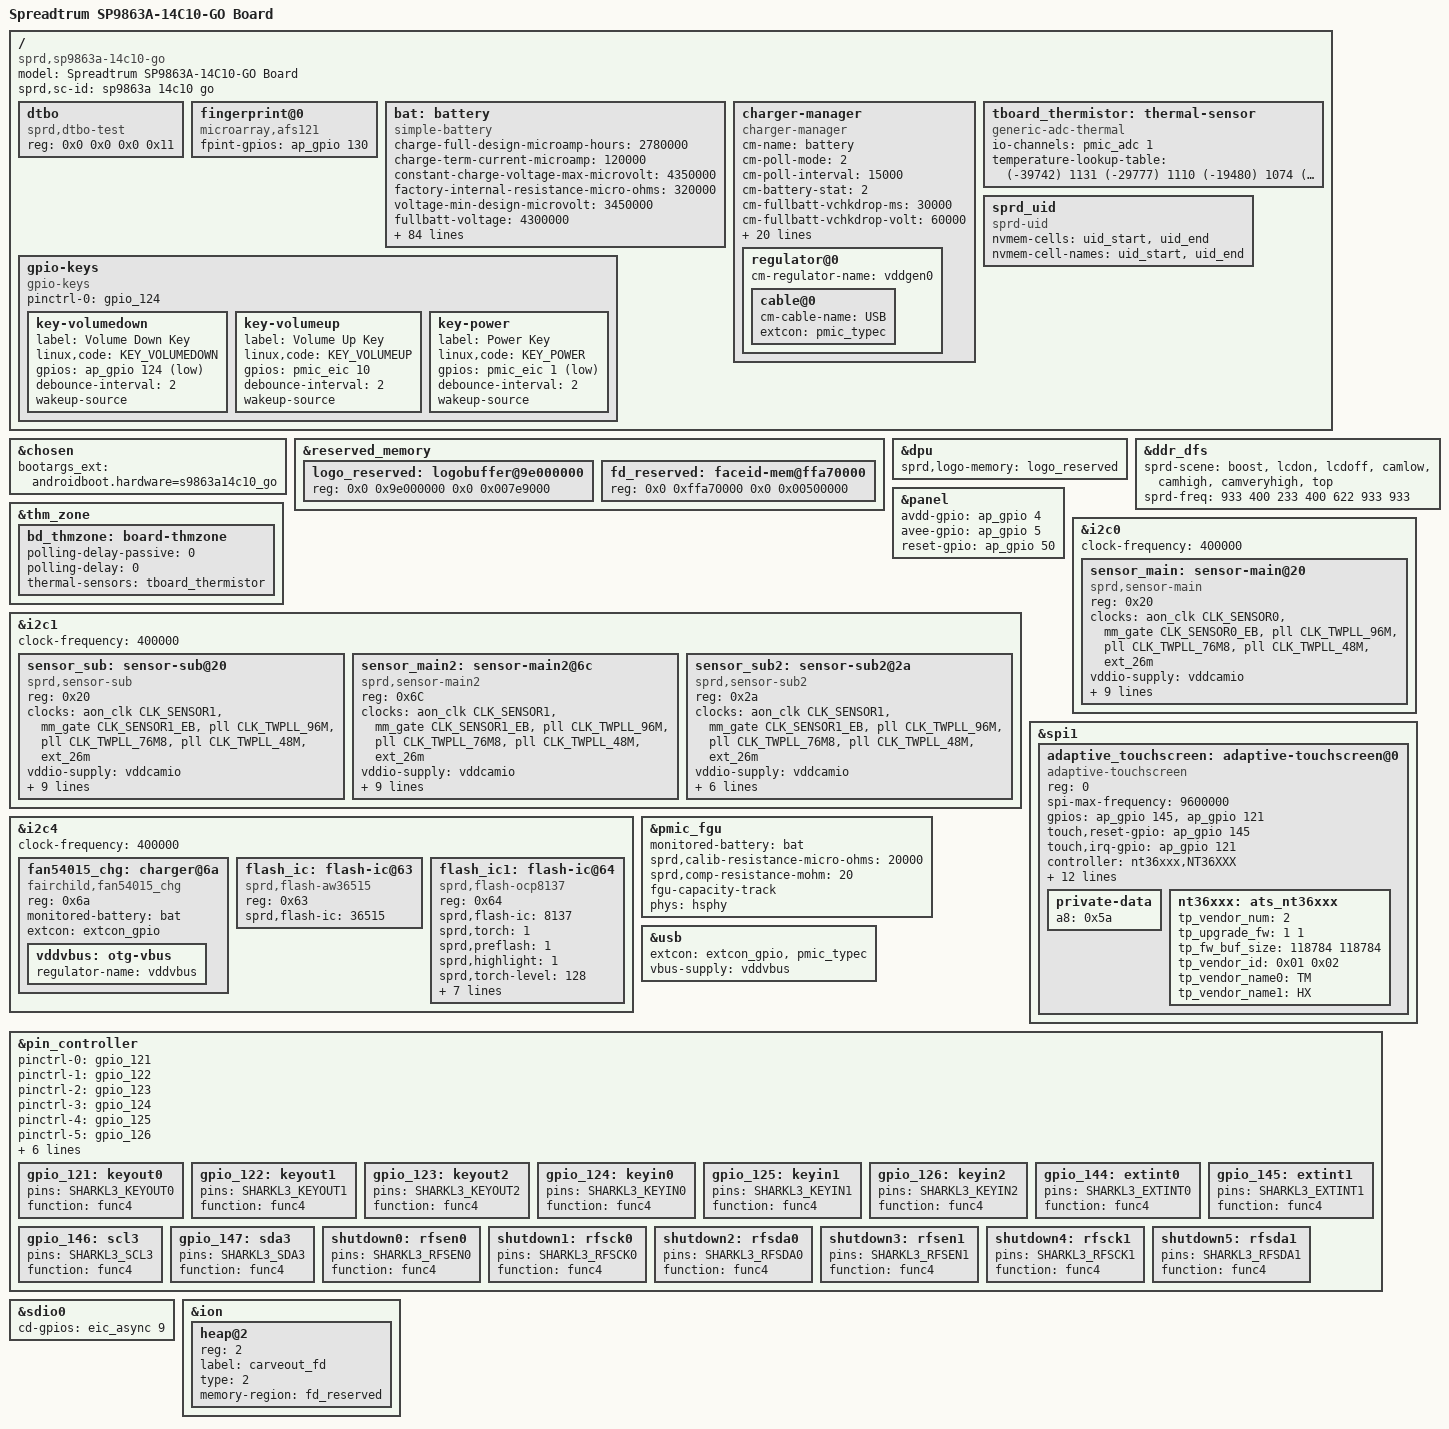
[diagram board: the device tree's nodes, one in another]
/dts-v1/;
/plugin/;
#include <dt-bindings/input/input.h>
#include <dt-bindings/gpio/gpio.h>
#include <dt-bindings/clock/sprd,sc9863a-clk.h>
#include "lcd/lcd_nt36525b_tm_mipi_hdp.dtsi"
#include "lcd/lcd_nt36525b_hx_mipi_hdp.dtsi"
#include "lcd/lcd_dummy_mipi.dtsi"

/ {
	model = "Spreadtrum SP9863A-14C10-GO Board";

	compatible = "sprd,sp9863a-14c10-go", "sprd,sc9863a";

	sprd,sc-id = "sp9863a 14c10 go";

	fragment {
		target-path = "/";
		__overlay__ {
			#address-cells = <2>;
			#size-cells = <2>;
			dtbo: dtbo {
				compatible = "sprd,dtbo-test";
				reg = <0x0 0x0 0x0 0x11>;
			};

			fingerprint@0 {
				compatible = "microarray,afs121";
				fpint-gpios = <&ap_gpio 130 0>;
			};

			bat: battery {
				compatible = "simple-battery";
				charge-full-design-microamp-hours = <2780000>;
				charge-term-current-microamp = <120000>;
				constant-charge-voltage-max-microvolt = <4350000>;
				factory-internal-resistance-micro-ohms = <320000>;
				voltage-min-design-microvolt = <3450000>;
				fullbatt-voltage = <4300000>;
				fullbatt-current = <120000>;
				fullbatt-track-end-vol = <4295000>;
				fullbatt-track-end-cur = <130000>;
				first-calib-voltage = <3554800>;
				first-calib-capacity = <50>;

				ocv-capacity-celsius = <20>;
				ocv-capacity-table-0 = <4330000 100>, <4249000 95>, <4189000 90>,
							<4133000 85>, <4081000 80>, <4034000 75>,
							<3991000 70>, <3953000 65>, <3910000 60>,
							<3866000 55>, <3836000 50>, <3813000 45>,
							<3795000 40>, <3782000 35>, <3774000 30>,
							<3765000 25>, <3750000 20>, <3726000 15>,
							<3687000 10>, <3658000 5>, <3400000 0>;
				voltage-temp-table = <1110270 800>, <999440 850>, <890430 900>,
							<785590 950>, <687630 1000>, <598220 1050>,
							<517680 1100>, <446100 1150>, <383390 1200>,
							<328950 1250>, <281840 1300>, <241480 1350>,
							<207030 1400>, <177580 1450>, <152490 1500>,
							<131160 1550>, <113000 1600>, <97790 1650>;
				capacity-temp-table = <25 100>, <10 97>, <(-10) 60>;
				resistance-temp-table = <20 100>, <10 243>, <(-10) 468>;

				battery-internal-resistance-celsius = <(-20)>, <(-10)>, <0>, <10>,
					<25>, <35>, <45>, <55>;
				battery-internal-resistance-table-0 = <1224>, <1224>, <1140>,
					<1084>, <1034>, <1001>, <994>, <992>, <992>, <992>,
					<996>, <1002>, <1010>, <1024>, <1045>, <1072>, <1180>,
					<1393>, <1756>, <2461>, <4272>;
				battery-internal-resistance-table-1 = <893>, <893>, <818>, <767>,
					<743>, <705>, <685>, <684>, <678>, <675>, <672>, <673>,
					<679>, <691>, <709>, <734>, <765>, <799>, <839>, <899>,
					<1092>;
				battery-internal-resistance-table-2 = <407>, <407>, <402>, <423>,
					<429>, <428>, <409>, <416>, <408>, <395>, <390>, <390>,
					<393>, <398>, <405>, <416>, <431>, <452>, <492>, <585>,
					<730>;
				battery-internal-resistance-table-3 = <381>, <381>, <378>, <371>,
					<366>, <374>, <358>, <364>, <349>, <332>, <327>, <329>,
					<334>, <340>, <350>, <366>, <386>, <417>, <475>, <585>,
					<771>;
				battery-internal-resistance-table-4 = <182>, <182>, <179>, <179>,
					<179>, <181>, <182>, <195>, <194>, <173>, <164>, <164>,
					<167>, <171>, <175>, <174>, <172>, <179>, <187>, <244>,
					<311>;
				battery-internal-resistance-table-5 = <168>, <168>, <175>, <172>,
					<171>, <171>, <173>, <184>, <176>, <153>, <147>, <147>,
					<150>, <153>, <156>, <152>, <149>, <154>, <158>, <206>,
					<255>;
				battery-internal-resistance-table-6 = <123>, <123>, <122>, <122>,
					<123>, <126>, <130>, <138>, <143>, <120>, <115>, <116>,
					<119>, <124>, <129>, <120>, <117>, <119>, <117>, <139>,
					<156>;
				battery-internal-resistance-table-7 = <106>, <106>, <106>, <106>,
					<108>, <110>, <113>, <119>, <128>, <107>, <104>, <105>,
					<108>, <112>, <117>, <107>, <106>, <107>, <105>, <127>,
					<140>;
				battery-internal-resistance-ocv-table = <4339000>, <4276000>,
					<4221000>, <4169000>, <4118000>, <4072000>, <4022000>,
					<3983000>, <3942000>, <3892000>, <3857000>, <3833000>,
					<3813000>, <3797000>, <3783000>, <3766000>, <3746000>,
					<3723000>, <3693000>, <3680000>, <3439000>;

				charge-sdp-current-microamp = <500000 500000>;
				charge-dcp-current-microamp = <1150000 3000000>;
				charge-cdp-current-microamp = <1150000 1150000>;
				charge-unknown-current-microamp = <500000 500000>;

				dcp-jeita-temp-table = <1000 1030 0 4350000>,
					<1150 1180 700000 4350000>,
					<1450 1420 1150000 4350000>,
					<1600 1570 700000 4100000>;
				sdp-jeita-temp-table = <1000 1030 0 4350000>,
					<1150 1180 500000 4350000>,
					<1450 1420 500000 4350000>,
					<1600 1570 500000 4100000>;
				cdp-jeita-temp-table = <1000 1030 0 4350000>,
					<1150 1180 700000 4350000>,
					<1450 1420 1150000 4350000>,
					<1600 1570 700000 4100000>;
				unknown-jeita-temp-table = <1000 1030 0 4350000>,
					<1150 1180 500000 4350000>,
					<1450 1420 500000 4350000>,
					<1600 1570 500000 4100000>;
				force-jeita-status = <2>;
			};

			charger-manager {
				status = "okay";
				compatible = "charger-manager";
				cm-name = "battery";
				cm-poll-mode = <2>;
				cm-poll-interval = <15000>;
				cm-battery-stat = <2>;

				cm-fullbatt-vchkdrop-ms = <30000>;
				cm-fullbatt-vchkdrop-volt = <60000>;
				cm-fullbatt-capacity = <100>;

				cm-chargers = "fan54015_charger";
				cm-fuel-gauge = "sc27xx-fgu";

				/* in deci centigrade */
				cm-battery-cold = <200>;
				cm-battery-cold-in-minus;
				cm-battery-hot = <800>;
				cm-battery-temp-diff = <100>;

				/* Allow charging for 6hr */
				cm-charging-max = <21600000>;
				/* recovery charging after stop charging 45min */
				cm-discharging-max = <2700000>;

				/* the interval to feed charger watchdog */
				cm-wdt-interval = <60>;

				/* drop voltage in microVolts to allow shutdown */
				cm-shutdown-voltage = <3100000>;

				/* when 99% of the time is exceeded, it will be forced to 100% */
				cm-tickle-time-out = <1500>;

				/* how much time to allow capacity change */
				cm-one-cap-time = <30>;

				/* when the safe charging voltage is exceeded, stop charging */
				cm-charge-voltage-max = <6500000>;
				/* drop voltage in microVolts to restart charging */
				cm-charge-voltage-drop = <700000>;

				monitored-battery = <&bat>;

				cm-thermal-zone = "board-thmzone";

				cm-cap-remap-table = <1 2 3>, <2 3 2>, <98 99 2>, <99 100 3>;

				phys = <&hsphy>;

				regulator@0 {
					cm-regulator-name = "vddgen0";
					cable@0 {
						cm-cable-name = "USB";
						extcon = <&pmic_typec>;
					};
				};
			};

			tboard_thermistor:thermal-sensor {
				compatible = "generic-adc-thermal";
				#thermal-sensor-cells = <0>;
				io-channels = <&pmic_adc 1>;
				io-channel-names = "sensor-channel";
				temperature-lookup-table = < (-39742) 1131
							(-29777) 1110
							(-19480) 1074
							(-4679) 983
							10110 838
							24805 654
							44922 413
							54903 316
							64895 238
							74884 178
							84883 133
							94883 100
							104880 75
							114889 57
							124872 43 >;
			};

			gpio-keys {
				compatible = "gpio-keys";
				pinctrl-names = "gpio_124";
				pinctrl-0 = <&gpio_124>;
				key-volumedown {
					label = "Volume Down Key";
					linux,code = <KEY_VOLUMEDOWN>;
					gpios = <&ap_gpio 124 GPIO_ACTIVE_LOW>;
					debounce-interval = <2>;
					wakeup-source;
				};
				key-volumeup {
					label = "Volume Up Key";
					linux,code = <KEY_VOLUMEUP>;
					gpios = <&pmic_eic 10 GPIO_ACTIVE_HIGH>;
					debounce-interval = <2>;
					wakeup-source;
				};
				key-power {
					label = "Power Key";
					linux,code =<KEY_POWER>;
					gpios = <&pmic_eic 1 GPIO_ACTIVE_LOW>;
					debounce-interval = <2>;
					wakeup-source;
				};
			};
			sprd_uid {
				compatible = "sprd-uid";
				nvmem-cells = <&uid_start>, <&uid_end>;
				nvmem-cell-names = "uid_start", "uid_end";
			};
		};
	};
};

&chosen {
	bootargs_ext = "androidboot.hardware=s9863a14c10_go";
};

&reserved_memory {
	#address-cells = <2>;
	#size-cells = <2>;

	logo_reserved: logobuffer@9e000000 {
		reg = <0x0 0x9e000000 0x0 0x007e9000>;
	};

	fd_reserved: faceid-mem@ffa70000{
		reg = <0x0 0xffa70000 0x0 0x00500000>;
	};
};

&dpu {
	sprd,logo-memory = <&logo_reserved>;
};


&ddr_dfs {
	sprd-scene = "boost", "lcdon", "lcdoff", "camlow",
		"camhigh", "camveryhigh", "top";
	sprd-freq = <933 400 233 400 622 933 933>;
};

&panel {
	avdd-gpio = <&ap_gpio 4 GPIO_ACTIVE_HIGH>;
	avee-gpio = <&ap_gpio 5 GPIO_ACTIVE_HIGH>;
	reset-gpio = <&ap_gpio 50 GPIO_ACTIVE_HIGH>;
};

&thm_zone {
	bd_thmzone: board-thmzone {
		polling-delay-passive = <0>;
		polling-delay = <0>;
		thermal-sensors = <&tboard_thermistor>;
	};
};

&i2c0 {
	#address-cells = <1>;
	#size-cells = <0>;

	status = "okay";
	clock-frequency = <400000>;

	sensor_main: sensor-main@20 {
		compatible = "sprd,sensor-main";
		reg = <0x20>;
		clock-names = "clk_src","sensor_eb",
			"clk_96m","clk_76m8",
			"clk_48m","clk_26m";
		clocks = <&aon_clk CLK_SENSOR0>, <&mm_gate CLK_SENSOR0_EB>,
			<&pll CLK_TWPLL_96M>,<&pll CLK_TWPLL_76M8>,
			<&pll CLK_TWPLL_48M>,<&ext_26m>;
		vddio-supply = <&vddcamio>;
		vddcama-supply = <&vddcama>;
		vddcamd-supply = <&vddcamd>;
		vddcammot-supply = <&vddcammot>;
		avdd-gpios = <&ap_gpio 63 0>;
		sprd,phyid = <1>;
		csi = <&csi0>;
		reset-gpios = <&ap_gpio 44 0>;
		power-down-gpios = <&ap_gpio 46 0>;
		power-domains = <&mm_domain>;
	};
};

&i2c1 {
	#address-cells = <1>;
	#size-cells = <0>;

	status = "okay";
	clock-frequency = <400000>;

	sensor_sub: sensor-sub@20 {
		compatible = "sprd,sensor-sub";
		reg = <0x20>;
		clock-names = "clk_src","sensor_eb",
			"clk_96m","clk_76m8",
			"clk_48m","clk_26m";
		clocks = <&aon_clk CLK_SENSOR1>, <&mm_gate CLK_SENSOR1_EB>,
			<&pll CLK_TWPLL_96M>,<&pll CLK_TWPLL_76M8>,
			<&pll CLK_TWPLL_48M>,<&ext_26m>;
		vddio-supply = <&vddcamio>;
		vddcama-supply = <&vddcama>;
		vddcamd-supply = <&vddcamd>;
		vddcammot-supply = <&vddcammot>;
		avdd-gpios = <&ap_gpio 63 0>;
		sprd,phyid = <0>;
		csi = <&csi0>;
		reset-gpios = <&ap_gpio 41 0>;
		power-down-gpios = <&ap_gpio 40 0>;
		power-domains = <&mm_domain>;
	};

	sensor_main2: sensor-main2@6c {
		compatible = "sprd,sensor-main2";
		reg = <0x6C>;
		clock-names = "clk_src","sensor_eb",
			"clk_96m","clk_76m8",
			"clk_48m","clk_26m";
		clocks = <&aon_clk CLK_SENSOR1>, <&mm_gate CLK_SENSOR1_EB>,
			<&pll CLK_TWPLL_96M>,<&pll CLK_TWPLL_76M8>,
			<&pll CLK_TWPLL_48M>,<&ext_26m>;
		vddio-supply = <&vddcamio>;
		vddcama-supply = <&vddcama>;
		vddcamd-supply = <&vddcamd>;
		vddcammot-supply = <&vddcammot>;
		sprd,phyid = <3>;
		csi = <&csi1>;
		/*avdd-gpios=<&ap_gpio 140 0>;*/
		dvdd-gpios=<&ap_gpio 62 0>;
		reset-gpios = <&ap_gpio 45 0>;
		power-down-gpios = <&ap_gpio 47 0>;
		power-domains = <&mm_domain>;
	};

	sensor_sub2: sensor-sub2@2a {
		compatible = "sprd,sensor-sub2";
		reg = <0x2a>;
		clock-names = "clk_src","sensor_eb",
			"clk_96m","clk_76m8",
			"clk_48m","clk_26m";
		clocks = <&aon_clk CLK_SENSOR1>, <&mm_gate CLK_SENSOR1_EB>,
			<&pll CLK_TWPLL_96M>,<&pll CLK_TWPLL_76M8>,
			<&pll CLK_TWPLL_48M>,<&ext_26m>;
		vddio-supply = <&vddcamio>;
		vddcama-supply = <&vddcama>;
		avdd-gpios = <&ap_gpio 63 0>;
		power-down-gpios = <&ap_gpio 73 0>;
		sprd,phyid = <4>;
		csi = <&csi2>;
		power-domains = <&mm_domain>;
	};
};

&i2c4 {
	#address-cells = <1>;
	#size-cells = <0>;

	status = "okay";
	clock-frequency = <400000>;

	fan54015_chg: charger@6a {
		compatible = "fairchild,fan54015_chg";
		reg = <0x6a>;
		monitored-battery = <&bat>;
		extcon = <&extcon_gpio>;
		vddvbus:otg-vbus {
			regulator-name = "vddvbus";
		};
	};

	flash_ic: flash-ic@63 {
		compatible = "sprd,flash-aw36515";
		reg = <0x63>;
		sprd,flash-ic = <36515>;
	};

	flash_ic1: flash-ic@64 {
		compatible = "sprd,flash-ocp8137";
		reg = <0x64>;
		sprd,flash-ic = <8137>;
		sprd,torch = <1>;
		sprd,preflash = <1>;
		sprd,highlight = <1>;
		sprd,torch-level = <128>;
		sprd,preflash-level = <128>;
		sprd,highlight-level = <128>;
		sprd,lvfm-enable = <1>;
		flash-torch-en-gpios = <&ap_gpio 88 0>;
		flash-chip-en-gpios = <&ap_gpio 89 0>;
		flash-en-gpios = <&ap_gpio 76 0>;
		flash-sync-gpios = <&ap_gpio 141 0>;
	};
};

&spi1 {
	#address-cells = <1>;
	#size-cells = <0>;
	status = "okay";
	//clock-frequency = <400000>;

	adaptive_touchscreen: adaptive-touchscreen@0{
	    status = "okay";
		compatible = "adaptive-touchscreen";
		reg = <0>;
		spi-max-frequency = <9600000>;	//4800000,9600000,15000000,19200000
		gpios = <&ap_gpio 145 0
				    &ap_gpio 121 0>;
		touch,reset-gpio = <&ap_gpio 145 0>;
		touch,irq-gpio = <&ap_gpio 121 0>;
		controller = "nt36xxx,NT36XXX";
		novatek,swrst-n8-addr = <0x03F0FE>;
		novatek,spi-rd-fast-addr = <0x03F310>;
		/*virtualkeys = <80 1650 30 30
				240 1650 30 30
				400 1650 30 30>;
		TP_MAX_X = <720>;
		TP_MAX_Y = <1600>;*/
		tp_max_x = <720>;
		tp_max_y = <1600>;
		tp_avdd_supply = "1850";
		tp_point_max = <5>;
		tp_upgrade_switch = <1>;
		tp_esd_check = <0>;
		tp_ps_status = <0>;
		tp_sensorhub_status = <0>;
		tp_gesture_status = <1>;
		tp_ic_num = <1>;
		private-data{
			a8=/bits/ 8 <0x5a>;
		};
		nt36xxx:ats_nt36xxx {//62

			tp_vendor_num = <2>;
			tp_upgrade_fw = <1 1>;
			tp_fw_buf_size = <118784 118784>;
			tp_vendor_id = /bits/ 8 <0x01 0x02>;
			tp_vendor_name0 = "TM";
			tp_vendor_name1 = "HX";
			};

	};
};

&pmic_fgu {
	monitored-battery = <&bat>;
	sprd,calib-resistance-micro-ohms = <20000>;
	sprd,comp-resistance-mohm = <20>;

	fgu-capacity-track;
	phys = <&hsphy>;
};

&usb{
	extcon = <&extcon_gpio>, <&pmic_typec>;
	status = "okay";
	vbus-supply = <&vddvbus>;
};

&pin_controller {
	pinctrl-names =
	/* keyout0 ~ keyout2 */
	"gpio_121", "gpio_122", "gpio_123",
	/* keyin0 ~ keyin2 */
	"gpio_124", "gpio_125", "gpio_126",
	/* extint0, extint1, scl3, sda3 */
	"gpio_144", "gpio_145", "gpio_146", "gpio_147",
	/* Note:If create a new board,need to add the shutdown node */
	"shutdown";
	pinctrl-0 = <&gpio_121>;
	pinctrl-1 = <&gpio_122>;
	pinctrl-2 = <&gpio_123>;
	pinctrl-3 = <&gpio_124>;
	pinctrl-4 = <&gpio_125>;
	pinctrl-5 = <&gpio_126>;
	pinctrl-6 = <&gpio_144>;
	pinctrl-7 = <&gpio_145>;
	pinctrl-8 = <&gpio_146>;
	pinctrl-9 = <&gpio_147>;
	pinctrl-10 = <&shutdown0
			&shutdown1
			&shutdown2
			&shutdown3
			&shutdown4
			&shutdown5>;

	gpio_121: keyout0 {
		pins = "SHARKL3_KEYOUT0";
		function = "func4";
	};

	gpio_122: keyout1 {
		pins = "SHARKL3_KEYOUT1";
		function = "func4";
	};

	gpio_123: keyout2 {
		pins = "SHARKL3_KEYOUT2";
		function = "func4";
	};

	gpio_124: keyin0 {
		pins = "SHARKL3_KEYIN0";
		function = "func4";
	};

	gpio_125: keyin1 {
		pins = "SHARKL3_KEYIN1";
		function = "func4";
	};

	gpio_126: keyin2 {
		pins = "SHARKL3_KEYIN2";
		function = "func4";
	};

	gpio_144: extint0 {
		pins = "SHARKL3_EXTINT0";
		function = "func4";
	};

	gpio_145: extint1 {
		pins = "SHARKL3_EXTINT1";
		function = "func4";
	};

	gpio_146: scl3 {
		pins = "SHARKL3_SCL3";
		function = "func4";
	};

	gpio_147: sda3 {
		pins = "SHARKL3_SDA3";
		function = "func4";
	};

	shutdown0: rfsen0 {
		pins = "SHARKL3_RFSEN0";
		function = "func4";
	};

	shutdown1: rfsck0 {
		pins = "SHARKL3_RFSCK0";
		function = "func4";
	};

	shutdown2: rfsda0 {
		pins = "SHARKL3_RFSDA0";
		function = "func4";
	};

	shutdown3: rfsen1 {
		pins = "SHARKL3_RFSEN1";
		function = "func4";
	};

	shutdown4: rfsck1 {
		pins = "SHARKL3_RFSCK1";
		function = "func4";
	};

	shutdown5: rfsda1 {
		pins = "SHARKL3_RFSDA1";
		function = "func4";
	};
};

&sdio0 {
	cd-gpios = <&eic_async 9 0>;
};

&ion {
	#address-cells = <1>;
	#size-cells = <0>;

	heap@2 {
		reg = <2>;
		label = "carveout_fd";
		type = <2>;
		memory-region = <&fd_reserved>;
	};
};
